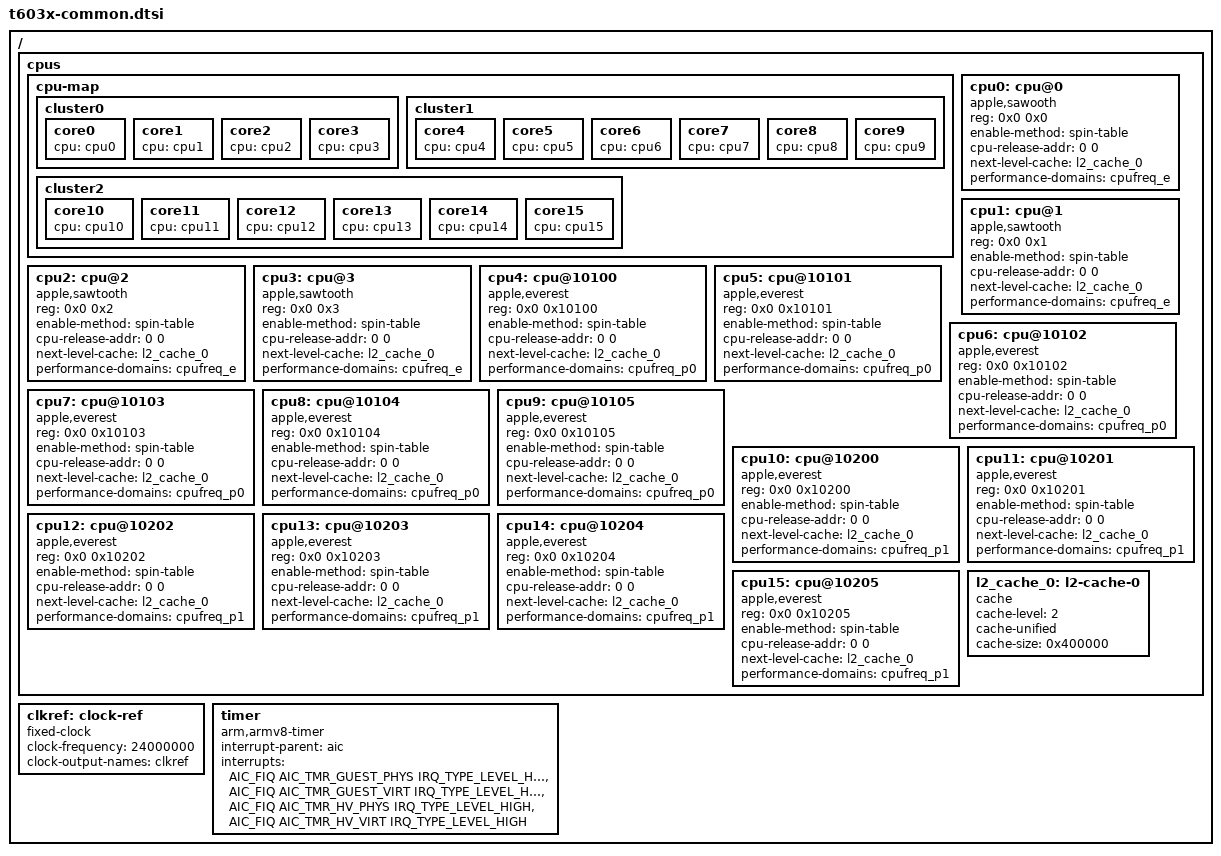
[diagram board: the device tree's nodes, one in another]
// SPDX-License-Identifier: GPL-2.0+ OR MIT
/*
 * Nodes common to all T603x family SoCs (M3 Pro/Max/Ultra)
 *
 * Other names: 
 *
 * Copyright The Asahi Linux Contributors
 */

/ {
	#address-cells = <2>;
	#size-cells = <2>;

	cpus {
		#address-cells = <2>;
		#size-cells = <0>;

		cpu-map {
			cluster0 {
				core0 { cpu = <&cpu0>;};
				core1 { cpu = <&cpu1>;};
				core2 { cpu = <&cpu2>;};
				core3 { cpu = <&cpu3>;};

			};
			cluster1 {
				core4 { cpu = <&cpu4>; };
				core5 { cpu = <&cpu5>; };
				core6 { cpu = <&cpu6>; };
				core7 { cpu = <&cpu7>; };
				core8 { cpu = <&cpu8>; };				
				core9 { cpu = <&cpu9>; };
			};
			cluster2 {
				core10 { cpu = <&cpu10>; };
				core11 { cpu = <&cpu11>; };
				core12 { cpu = <&cpu12>; };
				core13 { cpu = <&cpu13>; };
				core14 { cpu = <&cpu14>; };
				core15 { cpu = <&cpu15>; };
			};
		};

		cpu0: cpu@0 {
			compatible = "apple,sawooth";
			device_type = "cpu";
			reg = <0x0 0x0>;
			enable-method = "spin-table";
			cpu-release-addr = <0 0>;
			next-level-cache = <&l2_cache_0>;
			performance-domains = <&cpufreq_e>;
		};

		cpu1: cpu@1 {
			compatible = "apple,sawtooth";
			device_type = "cpu";
			reg = <0x0 0x1>;
			enable-method = "spin-table";
			cpu-release-addr = <0 0>;
			next-level-cache = <&l2_cache_0>;
			performance-domains = <&cpufreq_e>;
		};

		cpu2: cpu@2 {
			compatible = "apple,sawtooth";
			device_type = "cpu";
			reg = <0x0 0x2>;
			enable-method = "spin-table";
			cpu-release-addr = <0 0>;
			next-level-cache = <&l2_cache_0>;
			performance-domains = <&cpufreq_e>;
		};

		cpu3: cpu@3 {
			compatible = "apple,sawtooth";
			device_type = "cpu";
			reg = <0x0 0x3>;
			enable-method = "spin-table";
			cpu-release-addr = <0 0>;
			next-level-cache = <&l2_cache_0>;
			performance-domains = <&cpufreq_e>;
		};

		cpu4: cpu@10100 {
			compatible = "apple,everest";
			device_type = "cpu";
			reg = <0x0 0x10100>;
			enable-method = "spin-table";
			cpu-release-addr = <0 0>;
			next-level-cache = <&l2_cache_0>;
			performance-domains = <&cpufreq_p0>;
		};

		cpu5: cpu@10101 {
			compatible = "apple,everest";
			device_type = "cpu";
			reg = <0x0 0x10101>;
			enable-method = "spin-table";
			cpu-release-addr = <0 0>;
			next-level-cache = <&l2_cache_0>;
			performance-domains = <&cpufreq_p0>;
		};

		cpu6: cpu@10102 {
			compatible = "apple,everest";
			device_type = "cpu";
			reg = <0x0 0x10102>;
			enable-method = "spin-table";
			cpu-release-addr = <0 0>;
			next-level-cache = <&l2_cache_0>;
			performance-domains = <&cpufreq_p0>;
		};

		cpu7: cpu@10103 {
			compatible = "apple,everest";
			device_type = "cpu";
			reg = <0x0 0x10103>;
			enable-method = "spin-table";
			cpu-release-addr = <0 0>;
			next-level-cache = <&l2_cache_0>;
			performance-domains = <&cpufreq_p0>;
		};

		cpu8: cpu@10104 {
			compatible = "apple,everest";
			device_type = "cpu";
			reg = <0x0 0x10104>;
			enable-method = "spin-table";
			cpu-release-addr = <0 0>;
			next-level-cache = <&l2_cache_0>;
			performance-domains = <&cpufreq_p0>;
		};

		cpu9: cpu@10105 {
			compatible = "apple,everest";
			device_type = "cpu";
			reg = <0x0 0x10105>;
			enable-method = "spin-table";
			cpu-release-addr = <0 0>;
			next-level-cache = <&l2_cache_0>;
			performance-domains = <&cpufreq_p0>;
		};

		cpu10: cpu@10200 {
			compatible = "apple,everest";
			device_type = "cpu";
			reg = <0x0 0x10200>;
			enable-method = "spin-table";
			cpu-release-addr = <0 0>;
			next-level-cache = <&l2_cache_0>;
			performance-domains = <&cpufreq_p1>;
		};

		cpu11: cpu@10201 {
			compatible = "apple,everest";
			device_type = "cpu";
			reg = <0x0 0x10201>;
			enable-method = "spin-table";
			cpu-release-addr = <0 0>;
			next-level-cache = <&l2_cache_0>;
			performance-domains = <&cpufreq_p1>;
		};

		cpu12: cpu@10202 {
			compatible = "apple,everest";
			device_type = "cpu";
			reg = <0x0 0x10202>;
			enable-method = "spin-table";
			cpu-release-addr = <0 0>;
			next-level-cache = <&l2_cache_0>;
			performance-domains = <&cpufreq_p1>;
		};

		cpu13: cpu@10203 {
			compatible = "apple,everest";
			device_type = "cpu";
			reg = <0x0 0x10203>;
			enable-method = "spin-table";
			cpu-release-addr = <0 0>;
			next-level-cache = <&l2_cache_0>;
			performance-domains = <&cpufreq_p1>;
		};

		cpu14: cpu@10204 {
			compatible = "apple,everest";
			device_type = "cpu";
			reg = <0x0 0x10204>;
			enable-method = "spin-table";
			cpu-release-addr = <0 0>;
			next-level-cache = <&l2_cache_0>;
			performance-domains = <&cpufreq_p1>;
		};

		cpu15: cpu@10205 {
			compatible = "apple,everest";
			device_type = "cpu";
			reg = <0x0 0x10205>;
			enable-method = "spin-table";
			cpu-release-addr = <0 0>;
			next-level-cache = <&l2_cache_0>;
			performance-domains = <&cpufreq_p1>;
		};

		l2_cache_0: l2-cache-0 {
			compatible = "cache";
			cache-level = <2>;
			cache-unified;
			cache-size = <0x400000>;
		};
	};

clkref: clock-ref {
		compatible = "fixed-clock";
		#clock-cells = <0>;
		clock-frequency = <24000000>;
		clock-output-names = "clkref";
	};

timer {
		compatible = "arm,armv8-timer";
		interrupt-parent = <&aic>;
		interrupt-names = "phys", "virt", "hyp-phys", "hyp-virt";
		interrupts = <AIC_FIQ AIC_TMR_GUEST_PHYS IRQ_TYPE_LEVEL_HIGH>,
			     <AIC_FIQ AIC_TMR_GUEST_VIRT IRQ_TYPE_LEVEL_HIGH>,
			     <AIC_FIQ AIC_TMR_HV_PHYS IRQ_TYPE_LEVEL_HIGH>,
			     <AIC_FIQ AIC_TMR_HV_VIRT IRQ_TYPE_LEVEL_HIGH>;
	};


};
